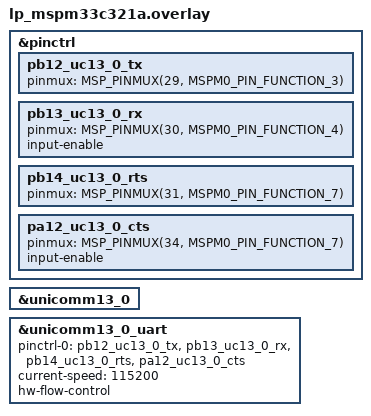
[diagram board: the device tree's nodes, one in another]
/*
 * Copyright (c) 2026 Texas Instruments Incorporated
 *
 * SPDX-License-Identifier: Apache-2.0
 */

/* TX (PB12/PINCM29) and RX (PB13/PINCM30) must be connected together for loopback */
/* RTS (PB14/PINCM31) and CTS (PA12/PINCM34) must be connected together for flow control */

&pinctrl {
	pb12_uc13_0_tx: pb12_uc13_0_tx {
		pinmux = <MSP_PINMUX(29, MSPM0_PIN_FUNCTION_3)>;
	};

	pb13_uc13_0_rx: pb13_uc13_0_rx {
		pinmux = <MSP_PINMUX(30, MSPM0_PIN_FUNCTION_4)>;
		input-enable;
	};

	pb14_uc13_0_rts: pb14_uc13_0_rts {
		pinmux = <MSP_PINMUX(31, MSPM0_PIN_FUNCTION_7)>;
	};

	pa12_uc13_0_cts: pa12_uc13_0_cts {
		pinmux = <MSP_PINMUX(34, MSPM0_PIN_FUNCTION_7)>;
		input-enable;
	};
};

&unicomm13_0 {
	status = "okay";
};

dut: &unicomm13_0_uart {
	pinctrl-0 = <&pb12_uc13_0_tx &pb13_uc13_0_rx &pb14_uc13_0_rts &pa12_uc13_0_cts>;
	pinctrl-names = "default";
	current-speed = <115200>;
	hw-flow-control;
	status = "okay";
};
